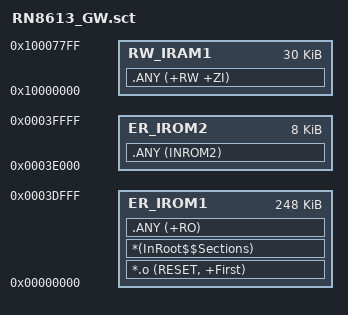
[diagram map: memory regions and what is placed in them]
; *************************************************************
; *** Scatter-Loading Description File generated by uVision ***
; *************************************************************

LR_IROM1 0x00000000 0x0003E000  {    ; load region size_region
  ER_IROM1 0x00000000 0x0003E000  {  ; load address = execution address
   *.o (RESET, +First)
   *(InRoot$$Sections)
   .ANY (+RO)
  }
  RW_IRAM1 0x10000000 0x00007800  {  ; RW data
   .ANY (+RW +ZI)
  }
}

LR_IROM2 0x0003E000  0x00002000  {
  ER_IROM2 0x0003E000  0x00002000  {  ; load address = execution address
   .ANY (INROM2)
  }
}
